# CH32V00xxx register map
Vendor: WCH; File version: 2024.09.30
Registers are 32-bit, read-write, reset 0x0 unless marked. A register's access mark holds for its fields unless they carry their own. Offsets are from the block's base; [hi:lo] are bit positions; {n}, {i} and the like mark numbered series.

## ESIG — Device electronic signature
Base 0x1FFFF7E0
0x00 FLACAP 16-bit ro — Flash capacity register
  [15:0] F_SIZE_15_0 — Flash size
{0x4+4i} UNIID{i} ro (i=1..3) — Unique identity {i}
  [31:0] U_ID — Unique identity[{32i-1}:{32i-32}]

## EXTEN — Extend configuration
Base 0x40023800
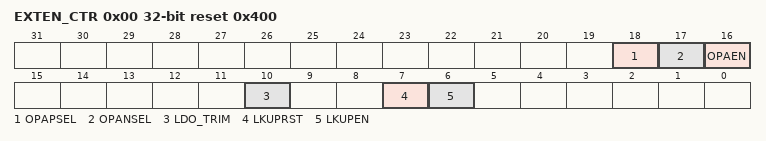
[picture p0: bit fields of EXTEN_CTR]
0x00 EXTEN_CTR access per field reset 0x400 — Configure the extended control register
  [18] OPAPSEL rw — OPA positive end channel selection
  [17] OPANSEL rw — OPA negative end channel selection
  [16] OPAEN rw — OPA Enalbe
  [10] LDO_TRIM rw
  [7] LKUPRST read/clear — LOCKUP RESET
  [6] LKUPEN rw — LOCKUP_Enable

## EXTI
Base 0x40010400
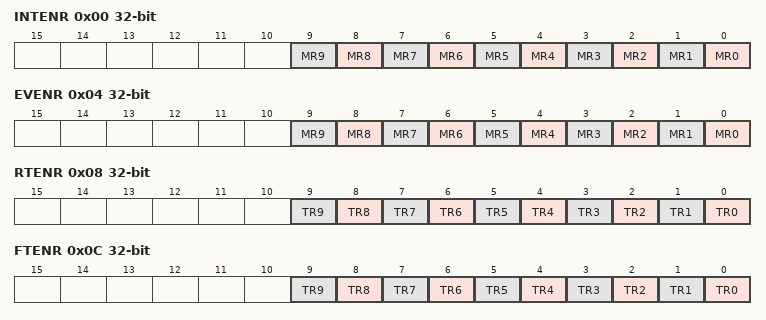
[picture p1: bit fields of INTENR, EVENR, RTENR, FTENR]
0x00 INTENR — Interrupt mask register (EXTI_INTENR)
  [n] MR{n} (n=0..9) — Interrupt Mask on line {n}
0x04 EVENR — Event mask register (EXTI_EVENR)
  [n] MR{n} (n=0..9) — Event Mask on line {n}
0x08 RTENR — Rising Trigger selection register (EXTI_RTENR)
  [n] TR{n} (n=0..9) — Rising trigger event configuration of line {n}
0x0C FTENR — Falling Trigger selection register (EXTI_FTENR)
  [n] TR{n} (n=0..9) — Falling trigger event configuration of line {n}
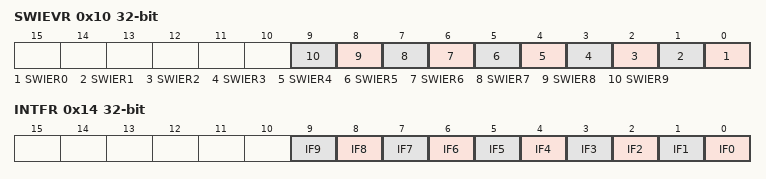
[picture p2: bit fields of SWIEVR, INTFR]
0x10 SWIEVR — Software interrupt event register (EXTI_SWIEVR)
  [n] SWIER{n} (n=0..9) — Software Interrupt on line {n}
0x14 INTFR — Pending register (EXTI_INTFR)
  [n] IF{n} (n=0..9) — Pending bit {n}

## FLASH
Base 0x40022000
0x00 ACTLR — Flash key register
  [1:0] LATENCY — Number of FLASH wait states
0x04 KEYR wo — Flash key register
  [31:0] KEYR — FPEC key
0x08 OBKEYR wo — Flash option key register
  [31:0] OPTKEY — Option byte key
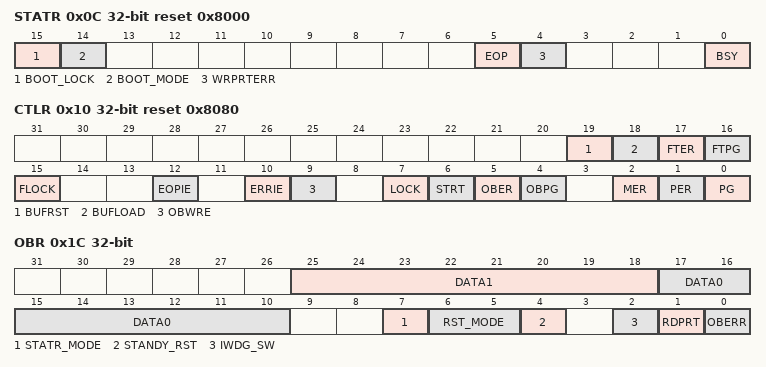
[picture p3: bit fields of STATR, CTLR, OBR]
0x0C STATR access per field reset 0x8000 — Status register
  [15] BOOT_LOCK rw
  [14] BOOT_MODE rw
  [5] EOP rw — End of operation
  [4] WRPRTERR rw — Write protection error
  [0] BSY ro — Busy
0x10 CTLR reset 0x8080 — Control register
  [19] BUFRST — Buffer reset
  [18] BUFLOAD — Buffer load
  [17] FTER — Fast erase
  [16] FTPG — Fast programming
  [15] FLOCK — Fast programmable lock
  [12] EOPIE — End of operation interrupt enable
  [10] ERRIE — Error interrupt enable
  [9] OBWRE — Option bytes write enable
  [7] LOCK
  [6] STRT — Start
  [5] OBER — Option byte erase
  [4] OBPG — Option byte programming
  [2] MER — Mass Erase
  [1] PER — Page Erase
  [0] PG — Programming
0x14 ADDR wo — Flash address register
  [31:0] FAR — Flash Address
0x1C OBR ro — Option byte register
  [25:18] DATA1
  [17:10] DATA0
  [7] STATR_MODE
  [6:5] RST_MODE — CFG_RST_MODE
  [4] STANDY_RST
  [2] IWDG_SW
  [1] RDPRT — Read protection
  [0] OBERR — Option byte error
0x20 WPR ro reset 0xFFFFFFFF — Write protection register
  [15:0] WRP — Write protect
0x24 MODEKEYR wo — Mode select register
  [31:0] MODEKEYR — Mode select
0x28 BOOT_MODEKEYP wo — Boot mode key register
  [31:0] MODEKEYR — Boot mode key

## GPIOA — General purpose I/O
Base 0x40010800
Same registers: GPIOC 0x40011000, GPIOD 0x40011400
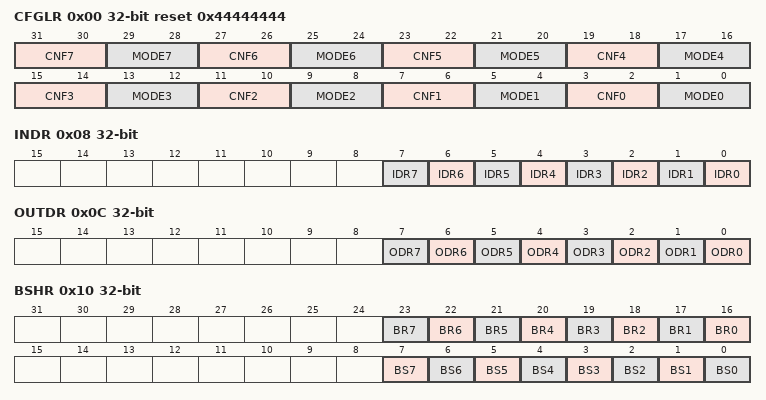
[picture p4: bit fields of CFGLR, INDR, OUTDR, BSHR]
0x00 CFGLR reset 0x44444444 — Port configuration register low (GPIOn_CFGLR)
  [31:30] CNF7 — Port n.7 configuration bits
  [29:28] MODE7 — Port n.7 mode bits
  [27:26] CNF6 — Port n.6 configuration bits
  [25:24] MODE6 — Port n.6 mode bits
  [23:22] CNF5 — Port n.5 configuration bits
  [21:20] MODE5 — Port n.5 mode bits
  [19:18] CNF4 — Port n.4 configuration bits
  [17:16] MODE4 — Port n.4 mode bits
  [15:14] CNF3 — Port n.3 configuration bits
  [13:12] MODE3 — Port n.3 mode bits
  [11:10] CNF2 — Port n.2 configuration bits
  [9:8] MODE2 — Port n.2 mode bits
  [7:6] CNF1 — Port n.1 configuration bits
  [5:4] MODE1 — Port n.1 mode bits
  [3:2] CNF0 — Port n.0 configuration bits
  [1:0] MODE0 — Port n.0 mode bits
0x08 INDR ro — Port input data register (GPIOn_INDR)
  [n] IDR{n} (n=0..7) — Port input data
0x0C OUTDR — Port output data register (GPIOn_OUTDR)
  [n] ODR{n} (n=0..7) — Port output data
0x10 BSHR wo — Port bit set/reset register (GPIOn_BSHR)
  [n+16] BR{n} (n=0..7) — Reset bit {n}
  [n] BS{n} (n=3..7) — Set bit {n}
  [2] BS2 — Set bit 1
  [1] BS1 — Set bit 1
  [0] BS0 — Set bit 0
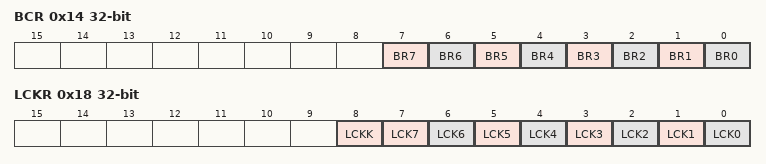
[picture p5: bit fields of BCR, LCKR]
0x14 BCR wo — Port bit reset register (GPIOn_BCR)
  [n] BR{n} (n=3..7) — Reset bit {n}
  [2] BR2 — Reset bit 1
  [1] BR1 — Reset bit 1
  [0] BR0 — Reset bit 0
0x18 LCKR — Port configuration lock register
  [8] LCKK — Lock key
  [n] LCK{n} (n=0..7) — Port A Lock bit {n}
